# AT32F455xx_v2 register map
Vendor: Keil; Series: AT32F455; File version: 1.0
CPU: CM4 r0p1, little endian, no MPU, FPU, 4 interrupt priority bits
Registers are 32-bit, read-write, reset 0x0 unless marked. A register's access mark holds for its fields unless they carry their own. Offsets are from the block's base; [hi:lo] are bit positions; {n}, {i} and the like mark numbered series; 'fields as' and 'values as' point back to an identical list.

## XMC — Flexible static memory controller
Base 0xA0000000
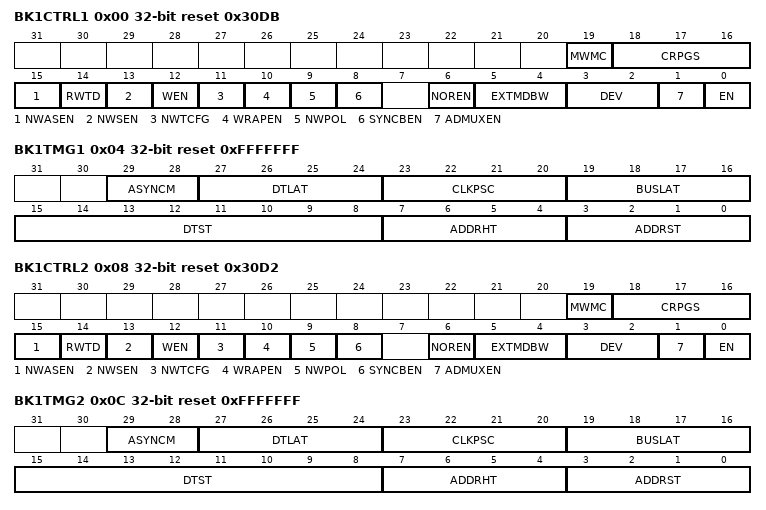
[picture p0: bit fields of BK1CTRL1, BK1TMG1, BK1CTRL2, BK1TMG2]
0x00 BK1CTRL1 reset 0x30DB — SRAM/NOR-Flash chip-select control register 1
  [19] MWMC — Memory write mode control
  [18:16] CRPGS — CRAM page size
  [15] NWASEN — NWAIT in asynchronous transfer enable
  [14] RWTD — Read-write timing different
  [13] NWSEN — NWAIT in synchronous transfer enable
  [12] WEN — Write enable
  [11] NWTCFG — Wait timing configuration
  [10] WRAPEN — Wrapped enable
  [9] NWPOL — NWAIT polarity
  [8] SYNCBEN — Synchronous burst enable
  [6] NOREN — Nor flash access enable
  [5:4] EXTMDBW — External memory data bus width
  [3:2] DEV — Memory device type
  [1] ADMUXEN — Address and data multiplexing enable
  [0] EN — Memory bank enable
0x04 BK1TMG1 reset 0xFFFFFFF — SRAM/NOR-Flash chip-select timing register 1
  [29:28] ASYNCM — Asynchronous mode
  [27:24] DTLAT — Data latency
  [23:20] CLKPSC — Clock prescale
  [19:16] BUSLAT — Bus latency
  [15:8] DTST — Asynchronous data setup time
  [7:4] ADDRHT — Address-hold time
  [3:0] ADDRST — Address setup time
0x08 BK1CTRL2 reset 0x30D2 — SRAM/NOR-Flash chip-select control register 2
  fields as BK1CTRL1
0x0C BK1TMG2 reset 0xFFFFFFF — SRAM/NOR-Flash chip-select timing register 2
  fields as BK1TMG1
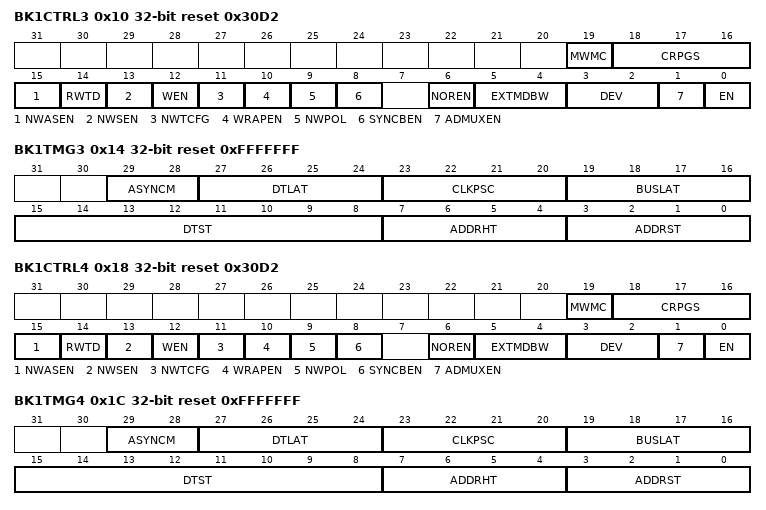
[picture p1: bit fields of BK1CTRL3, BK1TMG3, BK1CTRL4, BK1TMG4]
0x10 BK1CTRL3 reset 0x30D2 — SRAM/NOR-Flash chip-select control register 3
  fields as BK1CTRL1
0x14 BK1TMG3 reset 0xFFFFFFF — SRAM/NOR-Flash chip-select timing register 3
  fields as BK1TMG1
0x18 BK1CTRL4 reset 0x30D2 — SRAM/NOR-Flash chip-select control register 4
  fields as BK1CTRL1
0x1C BK1TMG4 reset 0xFFFFFFF — SRAM/NOR-Flash chip-select timing register 4
  fields as BK1TMG1
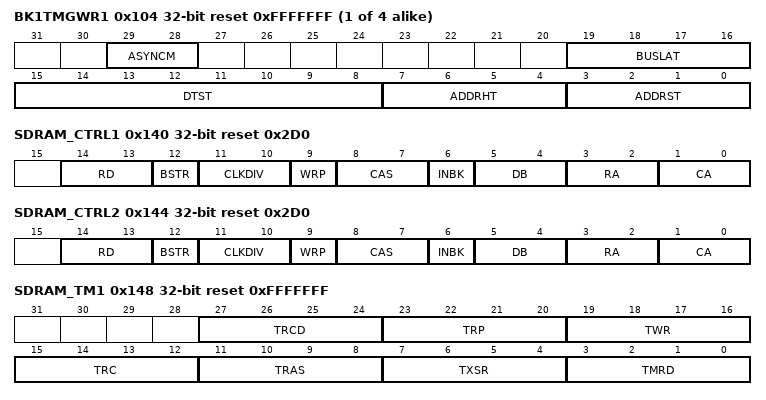
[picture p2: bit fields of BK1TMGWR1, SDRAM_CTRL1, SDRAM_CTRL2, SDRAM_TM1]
{0xFC+8i} BK1TMGWR{i} reset 0xFFFFFFF (i=1..4) — SRAM/NOR-Flash write timing registers {i}
  [29:28] ASYNCM — Asynchronous mode
  [19:16] BUSLAT — Bus latency
  [15:8] DTST — Asynchronous data setup time
  [7:4] ADDRHT — Address-hold time
  [3:0] ADDRST — Address setup time
0x140 SDRAM_CTRL1 reset 0x2D0 — SDRAM Control Register 1
  [14:13] RD — Read delay
  [12] BSTR — Burst read
  [11:10] CLKDIV — Clock division configuration
  [9] WRP — Write protection
  [8:7] CAS — CAS latency
  [6] INBK — Number of internal banks
  [5:4] DB — Memory data bus width
  [3:2] RA — Number of row address bits
  [1:0] CA — Number of column address bits
0x144 SDRAM_CTRL2 reset 0x2D0 — SDRAM Control Register 2
  [14:13] RD — Read pipe
  [12] BSTR — Burst read
  [11:10] CLKDIV — Clock division configuration
  [9] WRP — Write protection
  [8:7] CAS — CAS latency
  [6] INBK — Number of internal banks
  [5:4] DB — Memory data bus width
  [3:2] RA — Number of row address bits
  [1:0] CA — Number of column address bits
0x148 SDRAM_TM1 reset 0xFFFFFFF — SDRAM Timing register 1
  [27:24] TRCD — Row active to Read/Write delay
  [23:20] TRP — Precharge to active delay
  [19:16] TWR — Write Recovery delay
  [15:12] TRC — Refresh to active delay
  [11:8] TRAS — Self refresh time
  [7:4] TXSR — Exit Self-refresh to active delay
  [3:0] TMRD — Mode register program to active delay
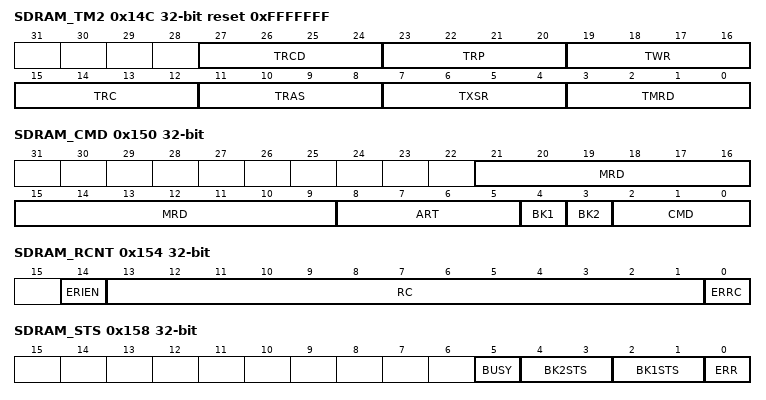
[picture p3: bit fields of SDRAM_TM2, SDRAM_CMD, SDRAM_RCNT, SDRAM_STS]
0x14C SDRAM_TM2 reset 0xFFFFFFF — SDRAM Timing register 2
  fields as SDRAM_TM1
0x150 SDRAM_CMD — SDRAM Command Mode register
  [21:9] MRD — Mode register data
  [8:5] ART — Auto-refresh times
  [4] BK1 wo — SDRAM Bank 1
  [3] BK2 wo — SDRAM Bank 2
  [2:0] CMD wo — SDRAM Command
0x154 SDRAM_RCNT — SDRAM Refresh Timer register
  [14] ERIEN — error Interrupt Enable
  [13:1] RC — Refresh Count
  [0] ERRC wo — error flag clear
0x158 SDRAM_STS ro — SDRAM Status register
  [5] BUSY — Busy status
  [4:3] BK2STS — Bank 2 Status
  [2:1] BK1STS — Bank 1 Status
  [0] ERR — error flag
0x180 SDRAM_CLKDIV1 — SDRAM clock 1 division
  [4] CLKDIV1 — Clock one division
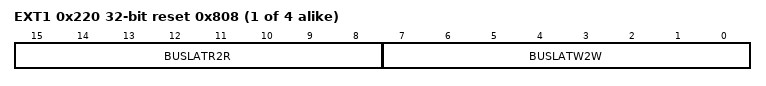
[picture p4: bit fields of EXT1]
{0x21C+4i} EXT{i} reset 0x808 (i=1..4) — externl timeing register {i}
  [15:8] BUSLATR2R — Bus turnaround phase for consecutive read duration
  [7:0] BUSLATW2W — Bus turnaround phase for consecutive write duration

## Notices in the file
Copyright (C) 2012-2014 ARM Limited. All rights reserved.
Purpose: System Viewer Description (SVD) Example (Schema Version 1.1)
This is a description of a none-existent and incomplete device
for demonstration purposes only.
Redistribution and use in source and binary forms, with or without
modification, are permitted provided that the following conditions are met:
- Redistributions of source code must retain the above copyright
notice, this list of conditions and the following disclaimer.
- Redistributions in binary form must reproduce the above copyright
notice, this list of conditions and the following disclaimer in the
documentation and/or other materials provided with the distribution.
- Neither the name of ARM nor the names of its contributors may be used
to endorse or promote products derived from this software without
specific prior written permission.
THIS SOFTWARE IS PROVIDED BY THE COPYRIGHT HOLDERS AND CONTRIBUTORS "AS IS"
AND ANY EXPRESS OR IMPLIED WARRANTIES, INCLUDING, BUT NOT LIMITED TO, THE
IMPLIED WARRANTIES OF MERCHANTABILITY AND FITNESS FOR A PARTICULAR PURPOSE
ARE DISCLAIMED. IN NO EVENT SHALL COPYRIGHT HOLDERS AND CONTRIBUTORS BE
LIABLE FOR ANY DIRECT, INDIRECT, INCIDENTAL, SPECIAL, EXEMPLARY, OR
CONSEQUENTIAL DAMAGES (INCLUDING, BUT NOT LIMITED TO, PROCUREMENT OF
SUBSTITUTE GOODS OR SERVICES; LOSS OF USE, DATA, OR PROFITS; OR BUSINESS
INTERRUPTION) HOWEVER CAUSED AND ON ANY THEORY OF LIABILITY, WHETHER IN
CONTRACT, STRICT LIABILITY, OR TORT (INCLUDING NEGLIGENCE OR OTHERWISE)
ARISING IN ANY WAY OUT OF THE USE OF THIS SOFTWARE, EVEN IF ADVISED OF THE
POSSIBILITY OF SUCH DAMAGE.
